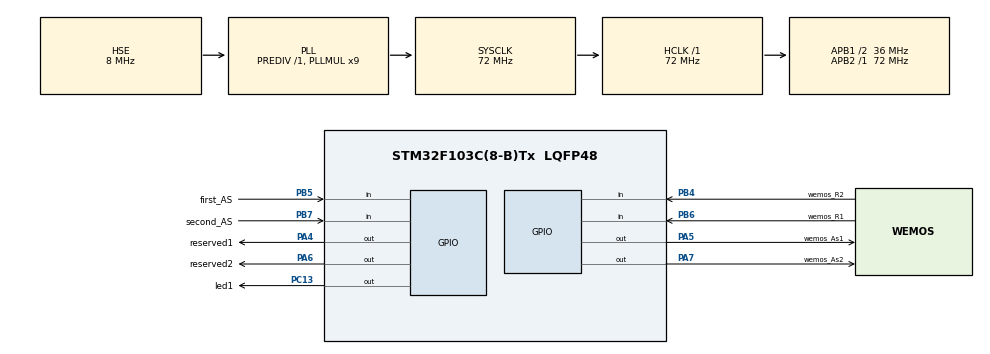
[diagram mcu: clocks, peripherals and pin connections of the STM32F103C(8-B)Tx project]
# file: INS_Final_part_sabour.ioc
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Mcu.Family=STM32F1
Mcu.Name=STM32F103C(8-B)Tx
Mcu.Package=LQFP48
NVIC.PriorityGroup=NVIC_PRIORITYGROUP_4
NVIC.TIM1_UP_IRQn=true\:0\:0\:false\:false\:true\:true\:true
PA13.Mode=Serial_Wire
PA13.Signal=SYS_JTMS-SWDIO
PA14.Mode=Serial_Wire
PA14.Signal=SYS_JTCK-SWCLK
PA4.GPIO_Label=reserved1
PA4.Signal=GPIO_Output
PA5.GPIO_Label=wemos_As1
PA5.Signal=GPIO_Output
PA6.GPIO_Label=reserved2
PA6.Signal=GPIO_Output
PA7.GPIO_Label=wemos_As2
PA7.Signal=GPIO_Output
PB4.GPIO_Label=wemos_R2
PB4.Signal=GPIO_Input
PB5.GPIO_Label=first_AS
PB5.Signal=GPIO_Input
PB6.GPIO_Label=wemos_R1
PB6.Signal=GPIO_Input
PB7.GPIO_Label=second_AS
PB7.Signal=GPIO_Input
PC13-TAMPER-RTC.GPIO_Label=led1
PC13-TAMPER-RTC.Signal=GPIO_Output
PD0-OSC_IN.Mode=HSE-External-Oscillator
PD0-OSC_IN.Signal=RCC_OSC_IN
PD1-OSC_OUT.Mode=HSE-External-Oscillator
PD1-OSC_OUT.Signal=RCC_OSC_OUT
ProjectManager.HeapSize=0x200
ProjectManager.StackSize=0x400
ProjectManager.TargetToolchain=MDK-ARM V5
RCC.AHBFreq_Value=72000000
RCC.APB1CLKDivider=RCC_HCLK_DIV2
RCC.APB1Freq_Value=36000000
RCC.APB1TimFreq_Value=72000000
RCC.APB2Freq_Value=72000000
RCC.APB2TimFreq_Value=72000000
RCC.HCLKFreq_Value=72000000
RCC.PLLMUL=RCC_PLL_MUL9
RCC.PLLSourceVirtual=RCC_PLLSOURCE_HSE
RCC.SYSCLKFreq_VALUE=72000000
RCC.SYSCLKSource=RCC_SYSCLKSOURCE_PLLCLK
RCC.USBFreq_Value=72000000
TIM1.AutoReloadPreload=TIM_AUTORELOAD_PRELOAD_ENABLE
TIM1.Period=10000
TIM1.Prescaler=7199
VP_TIM1_VS_ClockSourceINT.Mode=Internal
board=custom

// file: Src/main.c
/* USER CODE BEGIN Header */
/**
  ******************************************************************************
  * @file           : main.c
  * @brief          : Main program body
  ******************************************************************************
  * @attention
  *
  * <h2><center>&copy; Copyright (c) 2020 STMicroelectronics.
  * All rights reserved.</center></h2>
  *
  * This software component is licensed by ST under BSD 3-Clause license,
  * the "License"; You may not use this file except in compliance with the
  * License. You may obtain a copy of the License at:
  *                        opensource.org/licenses/BSD-3-Clause
  *
  ******************************************************************************
  */
/* USER CODE END Header */

#include "main.h"

/* USER CODE BEGIN PTD */
uint8_t count = 0;
uint8_t transmitFlag = 0;

/* USER CODE END PTD */

/* USER CODE BEGIN PD */
uint8_t read_Data[50];

/* USER CODE END PD */

TIM_HandleTypeDef htim1;

void SystemClock_Config(void);
static void MX_GPIO_Init(void);
static void MX_TIM1_Init(void);

int main(void)
{

  /* MCU Configuration--------------------------------------------------------*/

  /* Reset of all peripherals, Initializes the Flash interface and the Systick. */
  HAL_Init();

  /* Configure the system clock */
  SystemClock_Config();

  /* Initialize all configured peripherals */
  MX_GPIO_Init();
  MX_TIM1_Init();
  /* USER CODE BEGIN 2 */
  HAL_TIM_Base_Start_IT(&htim1);
  /* USER CODE END 2 */

  /* Infinite loop */
  while (1)
  {

	  if (transmitFlag == 1){
		  transmitFlag = 0;
		  HAL_GPIO_WritePin(wemos_As1_GPIO_Port, wemos_As1_Pin, read_Data[0]);
		  HAL_GPIO_WritePin(wemos_As2_GPIO_Port, wemos_As2_Pin, read_Data[1]);
		  HAL_GPIO_WritePin(reserved1_GPIO_Port, reserved1_Pin, read_Data[2]);
		  HAL_GPIO_WritePin(reserved2_GPIO_Port, reserved2_Pin, read_Data[3]);
		  HAL_GPIO_TogglePin(GPIOC, GPIO_PIN_13);
	  }

    /* USER CODE BEGIN 3 */
  }

}

void HAL_TIM_PeriodElapsedCallback(TIM_HandleTypeDef *htim){
	count ++ ;
	if (count > 1){
		read_Data[0] = HAL_GPIO_ReadPin(first_AS_GPIO_Port, first_AS_Pin);
		read_Data[1] = HAL_GPIO_ReadPin(second_AS_GPIO_Port, second_AS_Pin);
		read_Data[2] = HAL_GPIO_ReadPin(wemos_R1_GPIO_Port, wemos_R1_Pin);
		read_Data[3] = HAL_GPIO_ReadPin(wemos_R2_GPIO_Port, wemos_R2_Pin);
		transmitFlag = 1;
		count = 0;
	}
}

  /* USER CODE END 3 */

void SystemClock_Config(void)
{
  RCC_OscInitTypeDef RCC_OscInitStruct = {0};
  RCC_ClkInitTypeDef RCC_ClkInitStruct = {0};

  /** Initializes the CPU, AHB and APB busses clocks
  */
  RCC_OscInitStruct.OscillatorType = RCC_OSCILLATORTYPE_HSE;
  RCC_OscInitStruct.HSEState = RCC_HSE_ON;
  RCC_OscInitStruct.HSEPredivValue = RCC_HSE_PREDIV_DIV1;
  RCC_OscInitStruct.HSIState = RCC_HSI_ON;
  RCC_OscInitStruct.PLL.PLLState = RCC_PLL_ON;
  RCC_OscInitStruct.PLL.PLLSource = RCC_PLLSOURCE_HSE;
  RCC_OscInitStruct.PLL.PLLMUL = RCC_PLL_MUL9;
  if (HAL_RCC_OscConfig(&RCC_OscInitStruct) != HAL_OK)
  {
    Error_Handler();
  }
  /** Initializes the CPU, AHB and APB busses clocks
  */
  RCC_ClkInitStruct.ClockType = RCC_CLOCKTYPE_HCLK|RCC_CLOCKTYPE_SYSCLK
                              |RCC_CLOCKTYPE_PCLK1|RCC_CLOCKTYPE_PCLK2;
  RCC_ClkInitStruct.SYSCLKSource = RCC_SYSCLKSOURCE_PLLCLK;
  RCC_ClkInitStruct.AHBCLKDivider = RCC_SYSCLK_DIV1;
  RCC_ClkInitStruct.APB1CLKDivider = RCC_HCLK_DIV2;
  RCC_ClkInitStruct.APB2CLKDivider = RCC_HCLK_DIV1;

  if (HAL_RCC_ClockConfig(&RCC_ClkInitStruct, FLASH_LATENCY_2) != HAL_OK)
  {
    Error_Handler();
  }
}

static void MX_TIM1_Init(void)
{

  TIM_ClockConfigTypeDef sClockSourceConfig = {0};
  TIM_MasterConfigTypeDef sMasterConfig = {0};

  htim1.Instance = TIM1;
  htim1.Init.Prescaler = 7199;
  htim1.Init.CounterMode = TIM_COUNTERMODE_UP;
  htim1.Init.Period = 10000;
  htim1.Init.ClockDivision = TIM_CLOCKDIVISION_DIV1;
  htim1.Init.RepetitionCounter = 0;
  htim1.Init.AutoReloadPreload = TIM_AUTORELOAD_PRELOAD_ENABLE;
  if (HAL_TIM_Base_Init(&htim1) != HAL_OK)
  {
    Error_Handler();
  }
  sClockSourceConfig.ClockSource = TIM_CLOCKSOURCE_INTERNAL;
  if (HAL_TIM_ConfigClockSource(&htim1, &sClockSourceConfig) != HAL_OK)
  {
    Error_Handler();
  }
  sMasterConfig.MasterOutputTrigger = TIM_TRGO_RESET;
  sMasterConfig.MasterSlaveMode = TIM_MASTERSLAVEMODE_DISABLE;
  if (HAL_TIMEx_MasterConfigSynchronization(&htim1, &sMasterConfig) != HAL_OK)
  {
    Error_Handler();
  }

}

static void MX_GPIO_Init(void)
{
  GPIO_InitTypeDef GPIO_InitStruct = {0};

  /* GPIO Ports Clock Enable */
  __HAL_RCC_GPIOC_CLK_ENABLE();
  __HAL_RCC_GPIOD_CLK_ENABLE();
  __HAL_RCC_GPIOA_CLK_ENABLE();
  __HAL_RCC_GPIOB_CLK_ENABLE();

  /*Configure GPIO pin Output Level */
  HAL_GPIO_WritePin(led1_GPIO_Port, led1_Pin, GPIO_PIN_RESET);

  /*Configure GPIO pin Output Level */
  HAL_GPIO_WritePin(GPIOA, reserved1_Pin|wemos_As1_Pin|reserved2_Pin|wemos_As2_Pin, GPIO_PIN_RESET);

  /*Configure GPIO pin : led1_Pin */
  GPIO_InitStruct.Pin = led1_Pin;
  GPIO_InitStruct.Mode = GPIO_MODE_OUTPUT_PP;
  GPIO_InitStruct.Pull = GPIO_NOPULL;
  GPIO_InitStruct.Speed = GPIO_SPEED_FREQ_LOW;
  HAL_GPIO_Init(led1_GPIO_Port, &GPIO_InitStruct);

  /*Configure GPIO pins : reserved1_Pin wemos_As1_Pin reserved2_Pin Wemos_As2_Pin */
  GPIO_InitStruct.Pin = reserved1_Pin|wemos_As1_Pin|reserved2_Pin|wemos_As2_Pin;
  GPIO_InitStruct.Mode = GPIO_MODE_OUTPUT_PP;
  GPIO_InitStruct.Pull = GPIO_NOPULL;
  GPIO_InitStruct.Speed = GPIO_SPEED_FREQ_LOW;
  HAL_GPIO_Init(GPIOA, &GPIO_InitStruct);

  /*Configure GPIO pins : wemos_R2_Pin first_AS_Pin wemos_R1_Pin second_AS_Pin */
  GPIO_InitStruct.Pin = wemos_R2_Pin|first_AS_Pin|wemos_R1_Pin|second_AS_Pin;
  GPIO_InitStruct.Mode = GPIO_MODE_INPUT;
  GPIO_InitStruct.Pull = GPIO_NOPULL;
  HAL_GPIO_Init(GPIOB, &GPIO_InitStruct);

}

void Error_Handler(void)
{
}

/************************ (C) COPYRIGHT STMicroelectronics *****END OF FILE****/
